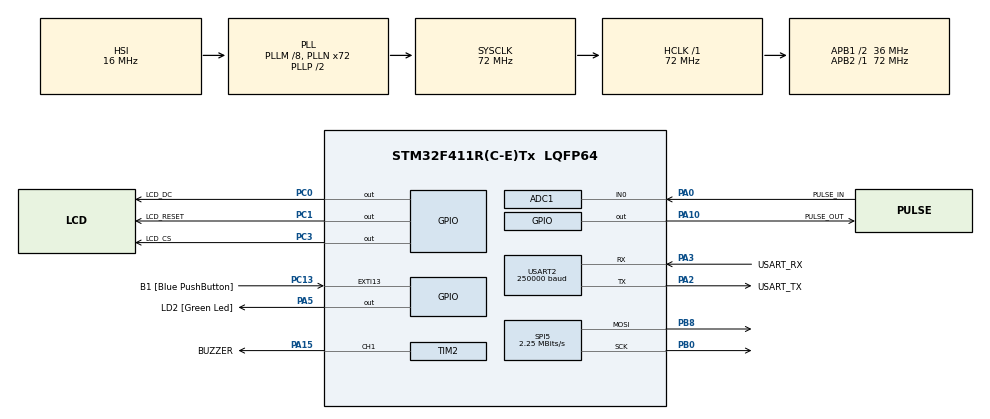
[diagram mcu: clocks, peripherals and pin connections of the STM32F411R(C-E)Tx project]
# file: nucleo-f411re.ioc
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ADC1.Channel-11\#ChannelRegularConversion=ADC_CHANNEL_0
ADC1.ContinuousConvMode=ENABLE
ADC1.DMAContinuousRequests=ENABLE
ADC1.NbrOfConversion=1
ADC1.NbrOfConversionFlag=1
ADC1.Rank-11\#ChannelRegularConversion=1
ADC1.Resolution=ADC_RESOLUTION_12B
ADC1.SamplingTime-11\#ChannelRegularConversion=ADC_SAMPLETIME_3CYCLES
ADC1.master=1
Dma.ADC1.0.Direction=DMA_PERIPH_TO_MEMORY
Dma.ADC1.0.FIFOMode=DMA_FIFOMODE_DISABLE
Dma.ADC1.0.Instance=DMA2_Stream0
Dma.ADC1.0.MemDataAlignment=DMA_MDATAALIGN_HALFWORD
Dma.ADC1.0.MemInc=DMA_MINC_ENABLE
Dma.ADC1.0.Mode=DMA_CIRCULAR
Dma.ADC1.0.PeriphDataAlignment=DMA_PDATAALIGN_HALFWORD
Dma.ADC1.0.PeriphInc=DMA_PINC_DISABLE
Dma.ADC1.0.Priority=DMA_PRIORITY_VERY_HIGH
Dma.Request0=ADC1
Dma.Request1=SPI5_TX
Dma.SPI5_TX.1.Direction=DMA_MEMORY_TO_PERIPH
Dma.SPI5_TX.1.FIFOMode=DMA_FIFOMODE_DISABLE
Dma.SPI5_TX.1.Instance=DMA2_Stream4
Dma.SPI5_TX.1.MemDataAlignment=DMA_MDATAALIGN_BYTE
Dma.SPI5_TX.1.MemInc=DMA_MINC_ENABLE
Dma.SPI5_TX.1.Mode=DMA_NORMAL
Dma.SPI5_TX.1.PeriphDataAlignment=DMA_PDATAALIGN_BYTE
Dma.SPI5_TX.1.PeriphInc=DMA_PINC_DISABLE
Dma.SPI5_TX.1.Priority=DMA_PRIORITY_VERY_HIGH
Mcu.Family=STM32F4
Mcu.Name=STM32F411R(C-E)Tx
Mcu.Package=LQFP64
NVIC.PriorityGroup=NVIC_PRIORITYGROUP_0
NVIC.TIM1_UP_TIM10_IRQn=true\:0\:0\:false\:false\:true\:true\:true\:true
PA0-WKUP.GPIO_Label=PULSE_IN
PA0-WKUP.Signal=ADCx_IN0
PA10.GPIO_Label=PULSE_OUT
PA10.Signal=GPIO_Output
PA13.GPIO_Label=TMS
PA13.Mode=Serial_Wire
PA13.Signal=SYS_JTMS-SWDIO
PA14.GPIO_Label=TCK
PA14.Mode=Serial_Wire
PA14.Signal=SYS_JTCK-SWCLK
PA15.GPIO_Label=BUZZER
PA15.Signal=S_TIM2_CH1_ETR
PA2.GPIO_Label=USART_TX
PA2.Mode=Asynchronous
PA2.Signal=USART2_TX
PA3.GPIO_Label=USART_RX
PA3.Mode=Asynchronous
PA3.Signal=USART2_RX
PA5.GPIO_Label=LD2 [Green Led]
PA5.Signal=GPIO_Output
PB0.Mode=TX_Only_Simplex_Unidirect_Master
PB0.Signal=SPI5_SCK
PB3.GPIO_Label=SWO
PB3.Signal=SYS_JTDO-SWO
PB8.Mode=TX_Only_Simplex_Unidirect_Master
PB8.Signal=SPI5_MOSI
PC0.GPIO_Label=LCD_DC
PC0.Signal=GPIO_Output
PC1.GPIO_Label=LCD_RESET
PC1.Signal=GPIO_Output
PC13-ANTI_TAMP.GPIO_Label=B1 [Blue PushButton]
PC13-ANTI_TAMP.GPIO_ModeDefaultEXTI=GPIO_MODE_IT_FALLING
PC13-ANTI_TAMP.Signal=GPXTI13
PC14-OSC32_IN.Signal=RCC_OSC32_IN
PC15-OSC32_OUT.Signal=RCC_OSC32_OUT
PC3.GPIO_Label=LCD_CS
PC3.Signal=GPIO_Output
PH0\ -\ OSC_IN.Mode=HSE-External-Clock-Source
PH0\ -\ OSC_IN.Signal=RCC_OSC_IN
PH1\ -\ OSC_OUT.Mode=HSE-External-Clock-Source
PH1\ -\ OSC_OUT.Signal=RCC_OSC_OUT
ProjectManager.HeapSize=0x200
ProjectManager.StackSize=0x400
ProjectManager.TargetToolchain=Makefile
RCC.48MHZClocksFreq_Value=36000000
RCC.AHBFreq_Value=72000000
RCC.APB1CLKDivider=RCC_HCLK_DIV2
RCC.APB1Freq_Value=36000000
RCC.APB1TimFreq_Value=72000000
RCC.APB2Freq_Value=72000000
RCC.APB2TimFreq_Value=72000000
RCC.CortexFreq_Value=72000000
RCC.FLatency-AdvancedSettings=FLASH_LATENCY_2
RCC.HCLKFreq_Value=72000000
RCC.HSE_VALUE=8000000
RCC.HSI_VALUE=16000000
RCC.LSE_VALUE=32768
RCC.PLLM=8
RCC.PLLN=72
RCC.SYSCLKFreq_VALUE=72000000
RCC.SYSCLKSource=RCC_SYSCLKSOURCE_PLLCLK
RCC.VCOOutputFreq_Value=144000000
SH.ADCx_IN0.0=ADC1_IN0,IN0
SH.S_TIM2_CH1_ETR.0=TIM2_CH1,PWM Generation1 CH1
SPI5.BaudRatePrescaler=SPI_BAUDRATEPRESCALER_32
SPI5.CalculateBaudRate=2.25 MBits/s
SPI5.Direction=SPI_DIRECTION_2LINES
SPI5.Mode=SPI_MODE_MASTER
SPI5.VirtualType=VM_MASTER
TIM10.Period=71
TIM2.AutoReloadPreload=TIM_AUTORELOAD_PRELOAD_ENABLE
TIM2.Channel-PWM\ Generation1\ CH1=TIM_CHANNEL_1
TIM2.Period=999
TIM2.Prescaler=71
TIM2.Pulse-PWM\ Generation1\ CH1=5000
USART2.BaudRate=250000
USART2.VirtualMode=VM_ASYNC
VP_TIM10_VS_ClockSourceINT.Mode=Enable_Timer
VP_TIM2_VS_ClockSourceINT.Mode=Internal
board=NUCLEO-F411RE

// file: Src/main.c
/* USER CODE BEGIN Header */
/**
  ******************************************************************************
  * @file           : main.c
  * @brief          : Main program body
  ******************************************************************************
  * @attention
  *
  * Copyright (c) 2025 STMicroelectronics.
  * All rights reserved.
  *
  * This software is licensed under terms that can be found in the LICENSE file
  * in the root directory of this software component.
  * If no LICENSE file comes with this software, it is provided AS-IS.
  *
  ******************************************************************************
  */
/* USER CODE END Header */
#include "main.h"
#include "adc.h"
#include "dma.h"
#include "spi.h"
#include "tim.h"
#include "usart.h"
#include "gpio.h"

/* USER CODE BEGIN Includes */
#include "GitKop.h"
/* USER CODE END Includes */

void SystemClock_Config(void);

int main(void)
{

  /* MCU Configuration--------------------------------------------------------*/

  /* Reset of all peripherals, Initializes the Flash interface and the Systick. */
  HAL_Init();

  /* Configure the system clock */
  SystemClock_Config();

  /* Initialize all configured peripherals */
  MX_GPIO_Init();
  MX_DMA_Init();
  MX_USART2_UART_Init();
  MX_ADC1_Init();
  MX_TIM2_Init();
  MX_SPI5_Init();
  MX_TIM10_Init();
  /* USER CODE BEGIN 2 */
  GitKop_Init();
  /* USER CODE END 2 */

  /* Infinite loop */
  /* USER CODE BEGIN WHILE */
  while (1)
  {
    GitKop_Loop();
    /* USER CODE END WHILE */

  }
}

void SystemClock_Config(void)
{
  RCC_OscInitTypeDef RCC_OscInitStruct = {0};
  RCC_ClkInitTypeDef RCC_ClkInitStruct = {0};

  /** Configure the main internal regulator output voltage
  */
  __HAL_RCC_PWR_CLK_ENABLE();
  __HAL_PWR_VOLTAGESCALING_CONFIG(PWR_REGULATOR_VOLTAGE_SCALE1);

  /** Initializes the RCC Oscillators according to the specified parameters
  * in the RCC_OscInitTypeDef structure.
  */
  RCC_OscInitStruct.OscillatorType = RCC_OSCILLATORTYPE_HSI;
  RCC_OscInitStruct.HSIState = RCC_HSI_ON;
  RCC_OscInitStruct.HSICalibrationValue = RCC_HSICALIBRATION_DEFAULT;
  RCC_OscInitStruct.PLL.PLLState = RCC_PLL_ON;
  RCC_OscInitStruct.PLL.PLLSource = RCC_PLLSOURCE_HSI;
  RCC_OscInitStruct.PLL.PLLM = 8;
  RCC_OscInitStruct.PLL.PLLN = 72;
  RCC_OscInitStruct.PLL.PLLP = RCC_PLLP_DIV2;
  RCC_OscInitStruct.PLL.PLLQ = 4;
  if (HAL_RCC_OscConfig(&RCC_OscInitStruct) != HAL_OK)
  {
    Error_Handler();
  }

  /** Initializes the CPU, AHB and APB buses clocks
  */
  RCC_ClkInitStruct.ClockType = RCC_CLOCKTYPE_HCLK|RCC_CLOCKTYPE_SYSCLK
                              |RCC_CLOCKTYPE_PCLK1|RCC_CLOCKTYPE_PCLK2;
  RCC_ClkInitStruct.SYSCLKSource = RCC_SYSCLKSOURCE_PLLCLK;
  RCC_ClkInitStruct.AHBCLKDivider = RCC_SYSCLK_DIV1;
  RCC_ClkInitStruct.APB1CLKDivider = RCC_HCLK_DIV2;
  RCC_ClkInitStruct.APB2CLKDivider = RCC_HCLK_DIV1;

  if (HAL_RCC_ClockConfig(&RCC_ClkInitStruct, FLASH_LATENCY_2) != HAL_OK)
  {
    Error_Handler();
  }
}

void Error_Handler(void)
{
  __disable_irq();
  while (1)
  {
  }
}
